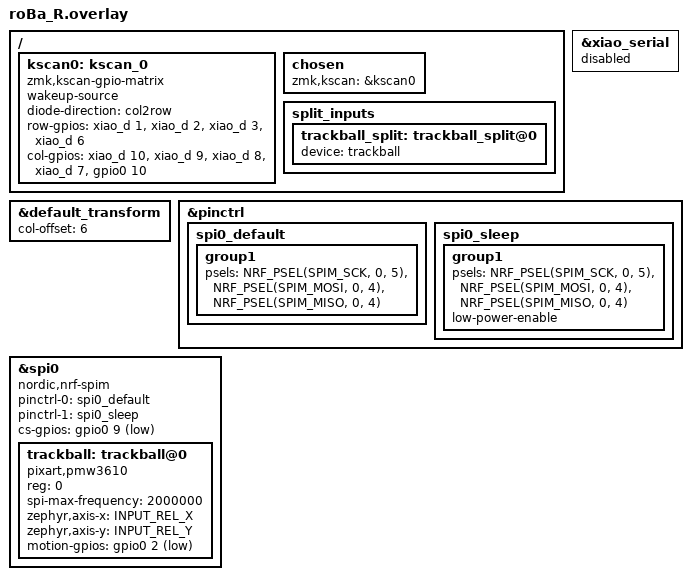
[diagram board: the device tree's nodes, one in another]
#include "roBa.dtsi"
#include <dt-bindings/input/input-event-codes.h>

&default_transform { col-offset = <6>; };
&xiao_serial { status = "disabled"; };

/ {
    kscan0: kscan_0 {
        compatible = "zmk,kscan-gpio-matrix";
        wakeup-source;
        diode-direction = "col2row";
        /* 公式順序 (6,3,2,1 ではなく 1,2,3,6 が正解の可能性が高い) */
        row-gpios
            = <&xiao_d 1 (GPIO_ACTIVE_HIGH | GPIO_PULL_DOWN)>
            , <&xiao_d 2 (GPIO_ACTIVE_HIGH | GPIO_PULL_DOWN)>
            , <&xiao_d 3 (GPIO_ACTIVE_HIGH | GPIO_PULL_DOWN)>
            , <&xiao_d 6 (GPIO_ACTIVE_HIGH | GPIO_PULL_DOWN)>;
        col-gpios
            = <&xiao_d 10 GPIO_ACTIVE_HIGH>
            , <&xiao_d 9 GPIO_ACTIVE_HIGH>
            , <&xiao_d 8 GPIO_ACTIVE_HIGH>
            , <&xiao_d 7 GPIO_ACTIVE_HIGH>
            , <&gpio0 10 GPIO_ACTIVE_HIGH>;
    };
    chosen { zmk,kscan = &kscan0; };

    /* split_inputs 定義 */
    split_inputs {
        trackball_split: trackball_split@0 {
            status = "okay";
            device = <&trackball>;
        };
    };
};

&pinctrl {
    spi0_default: spi0_default {
        group1 {
            psels = <NRF_PSEL(SPIM_SCK, 0, 5)>,
                    <NRF_PSEL(SPIM_MOSI, 0, 4)>,
                    <NRF_PSEL(SPIM_MISO, 0, 4)>;
        };
    };
    spi0_sleep: spi0_sleep {
        group1 {
            psels = <NRF_PSEL(SPIM_SCK, 0, 5)>,
                    <NRF_PSEL(SPIM_MOSI, 0, 4)>,
                    <NRF_PSEL(SPIM_MISO, 0, 4)>;
            low-power-enable;
        };
    };
};

&spi0 {
    status = "okay";
    compatible = "nordic,nrf-spim";
    pinctrl-0 = <&spi0_default>;
    pinctrl-1 = <&spi0_sleep>;
    pinctrl-names = "default", "sleep";
    cs-gpios = <&gpio0 9 GPIO_ACTIVE_LOW>;

    trackball: trackball@0 {
        status = "okay";
        compatible = "pixart,pmw3610";
        reg = <0>;
        spi-max-frequency = <2000000>;
        
        zephyr,axis-x = <INPUT_REL_X>;
        zephyr,axis-y = <INPUT_REL_Y>;

        motion-gpios = <&gpio0 2 (GPIO_ACTIVE_LOW | GPIO_PULL_UP)>;
        
        /* invert設定は公式にないので削除 */
    };
};
